# MU3E_FULL8LANE_TYPE0_SYSTEM_SC_HUB register map
Vendor: Mu3e; Series: MU3E_FULL8LANE_TYPE0; File version: 2026.05.06
Registers are 32-bit, read-write, reset 0x0 unless marked. A register's access mark holds for its fields unless they carry their own. Offsets are from the block's base; [hi:lo] are bit positions.

## DATA_PATH_SUBSYSTEM_HISTOGRAM_STATISTICS_0_CSR — Datapath-local slave expanded below the SC-hub mm_bridge.s0 aperture. Qsys slave data_path_subsystem_histogram_statistics_0.csr is SC-hub-relative at 0x0002A400 with compiled aperture size 0x00000080. Compiled Qsys module histogram_statistics_0 kind=full8lane_histogram_statistics_v2 version=26.1.8.502 from full8lane_type0_datapath.qsys. Version/identity parameters: VERSION_MAJOR=26, VERSION_MINOR=1, VERSION_PATCH=8, BUILD=502, VERSION_DATE=20260502, VERSION_GIT=72231161, IP_UID=1212765012, INSTANCE_ID=0. Source SVD histogram_statistics/histogram_statistics.svd version 26.1.6.0429. Relative 19-word CSR aperture for histogram statistics. The separate hist_bin data window is intentionally excluded because it is histogram memory, not control/status registers.
Base 0x0002A400
0x00 UID ro reset 0x48495354 — Software-visible IP identifier. Default ASCII "HIST" (0x48495354).
  [31:0] value — Compile-time or integration-time UID word. Default ASCII "HIST".
0x04 META — Read-multiplexed metadata word. Write meta_sel[1:0] before reading back: 0=VERSION, 1=DATE, 2=GIT, 3=INSTANCE_ID.
  [1:0] meta_sel — Selects the META read page.
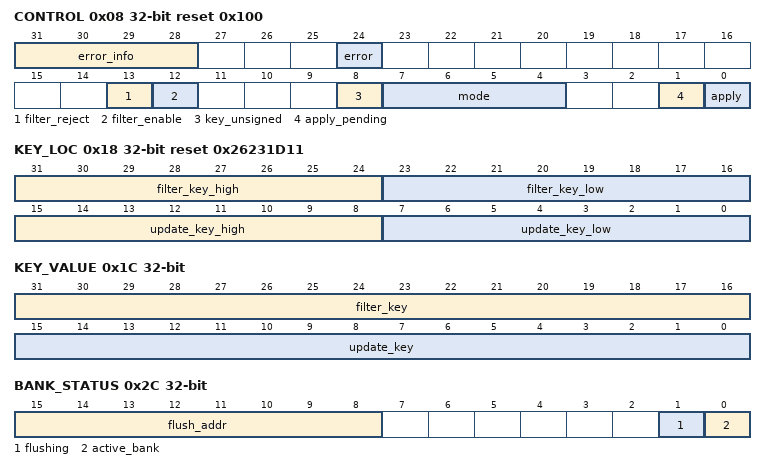
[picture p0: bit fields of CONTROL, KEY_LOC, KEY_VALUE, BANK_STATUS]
0x08 CONTROL reset 0x100 — Configuration apply, mode, key interpretation, filter control, and validation status.
  [31:28] error_info ro — Validation error code. 0x1 indicates invalid bounds in auto-right-bound mode.
  [24] error ro — Set when the last apply request failed CSR validation.
  [13] filter_reject — 0 accepts matching events, 1 rejects matching events.
  [12] filter_enable — Enables the runtime filter-key comparison.
  [8] key_unsigned — 1 selects unsigned update-key interpretation, 0 selects signed extraction.
  [7:4] mode — Mode selector. Negative signed values -1..-6 route debug_1..debug_6 individually; -7 samples signed MTS-delay streams on debug_1 and debug_2 together. In debug modes the CSR filter compares a synthetic debug word: bits [15:0] sample, [23:16] zero-based debug source, [31:24] absolute debug mode.
  [1] apply_pending ro — 1 while a committed configuration is waiting to settle into the live datapath.
  [0] apply — Write 1 to request that the staged configuration becomes active after the ingress path drains.
0x0C LEFT_BOUND — Signed left boundary of the histogram range.
  [31:0] value — Signed left boundary.
0x10 RIGHT_BOUND — Signed right boundary of the histogram range. Recomputed at apply time when BIN_WIDTH != 0.
  [31:0] value — Signed right boundary.
0x14 BIN_WIDTH — Bin width in key-space units. Set to 0 to keep explicit left and right bounds.
  [15:0] value — Bin width in key-space units.
0x18 KEY_LOC reset 0x26231D11 — Packed bit-slice locations for update-key and filter-key extraction.
  [31:24] filter_key_high — MSB of the filter-key slice inside the snooped data word. In debug modes this selects the synthetic debug word.
  [23:16] filter_key_low — LSB of the filter-key slice inside the snooped data word. In debug modes this selects the synthetic debug word.
  [15:8] update_key_high — MSB of the update-key slice inside the snooped data word.
  [7:0] update_key_low — LSB of the update-key slice inside the snooped data word.
0x1C KEY_VALUE — Packed runtime key overrides used by mode-dependent histogram logic.
  [31:16] filter_key — Literal filter-key comparison value.
  [15:0] update_key — Literal update-key override.
0x20 UNDERFLOW_COUNT ro — Count of keys mapped below the configured range.
  [31:0] value — Underflow event count.
0x24 OVERFLOW_COUNT ro — Count of keys mapped above the configured range.
  [31:0] value — Overflow event count.
0x28 INTERVAL_CFG — Ping-pong interval timer configuration in clock cycles.
  [31:0] value — Interval length in clock cycles.
0x2C BANK_STATUS ro — Ping-pong bank-selection and flush-progress status.
  [15:8] flush_addr — Bin index currently being cleared.
  [1] flushing — 1 while the next active bank is being cleared.
  [0] active_bank — Currently active write bank.
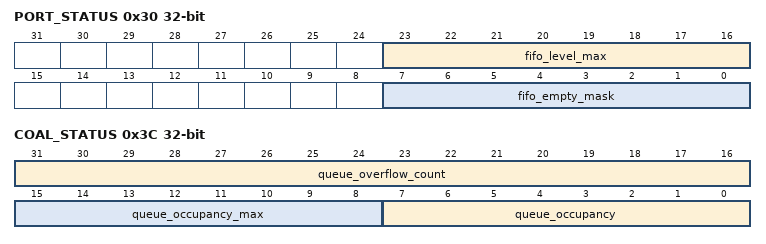
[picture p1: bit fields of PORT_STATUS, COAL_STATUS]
0x30 PORT_STATUS ro — Ingress FIFO empty-mask and maximum observed fill level.
  [23:16] fifo_level_max — Maximum observed FIFO fill level across the ingress-port pairs.
  [7:0] fifo_empty_mask — One bit per ingress FIFO. 1 indicates the corresponding FIFO is empty.
0x34 TOTAL_HITS ro — Live accepted-hit count in the current interval. Resets at manual clear and at every interval pulse.
  [31:0] value — Current-interval accepted-hit count.
0x38 DROPPED_HITS ro — Live dropped-hit count caused by FIFO or queue overflow in the current interval. Resets at manual clear and at every interval pulse.
  [31:0] value — Current-interval dropped-hit count.
0x3C COAL_STATUS ro — Coalescing-queue occupancy, occupancy maximum, and overflow count.
  [31:16] queue_overflow_count — Total number of queue-overflow events.
  [15:8] queue_occupancy_max — Maximum queue occupancy observed in the current interval.
  [7:0] queue_occupancy — Current coalescing-queue occupancy.
0x40 SCRATCH — General-purpose scratch register for integration testing.
  [31:0] value — Scratch value.
0x44 LAST_INTERVAL_TOTAL_HITS ro — Accepted-hit count latched at the most recent interval pulse before the live counter reset.
  [31:0] value — Last completed interval accepted-hit count.
0x48 LAST_INTERVAL_DROPPED_HITS ro — Dropped-hit count latched at the most recent interval pulse before the live counter reset.
  [31:0] value — Last completed interval dropped-hit count.
